# SWM190 register map
File version: 1.0
SWM190 Microcontroller registers
CPU: CM0 r1p0, little endian, 2 interrupt priority bits
Registers are 32-bit, read-write, no defined reset value unless marked. A register's access mark holds for its fields unless they carry their own. Offsets are from the block's base; lines under a group give offsets from that group; [hi:lo] are bit positions; {n}, {i} and the like mark numbered series; 'fields as' and 'values as' point back to an identical list; <NAME> marks a mode.

## Memory map
0x40000000 SYS size 0xAA088 — Registers group
0x40000800 DMA size 0x140 — Registers group
0x40003000 CORDIC size 0x20 — Registers group
0x40003800 DIV size 0x28 — Registers group
0x40005800 CACHE size 0x24 — Registers group
0x40040000 GPIOA size 0x80 — Registers group
0x40040800 GPIOB size 0x80
0x40041000 GPIOC size 0x80
0x40041800 GPIOD size 0x80
0x40042000 UART0 size 0x20 — Registers group
0x40042800 UART1 size 0x20
0x40043000 UART2 size 0x20
0x40043800 UART3 size 0x20
0x40044000 SPI0 size 0x24 — Registers group
0x40044800 SPI1 size 0x24
0x40046000 PWM0 size 0x3C — Registers group
0x40046040 PWM1 size 0x3C
0x40046080 PWM2 size 0x3C
0x400460C0 PWM3 size 0x3C
0x40046200 PWMG size 0x48 — Registers group
0x40046800 TIMR0 size 0x30 — Registers group
0x40046840 TIMR1 size 0x30
0x40046880 TIMR2 size 0x30
0x400468C0 TIMR3 size 0x30
0x40046C00 TIMRG size 0x44 — Registers group
0x40048800 BTIMR0 size 0x30
0x40048840 BTIMR1 size 0x30
0x40048880 BTIMR2 size 0x30
0x400488C0 BTIMR3 size 0x30
0x40048C00 BTIMRG size 0x44
0x40049000 ADC0 size 0xB4 — Registers group
0x40049800 ADC1 size 0xB4
0x4004A000 SFC size 0x28 — Registers group
0x4004B800 RTC size 0x34 — Registers group
0x400A0000 PORTA size 0x404 — Registers group
0x400A0010 PORTB size 0x404
0x400A0020 PORTC size 0x404
0x400A0030 PORTD size 0x404
0x400A0040 PORTE size 0x404
0x400A0800 WDT size 0x14 — Registers group
0x400A1000 GPIOE size 0x80
0x400A6000 I2C0 size 0x34 — Registers group
0x400A6800 I2C1 size 0x34

## SYS — Registers group
Base 0x40000000
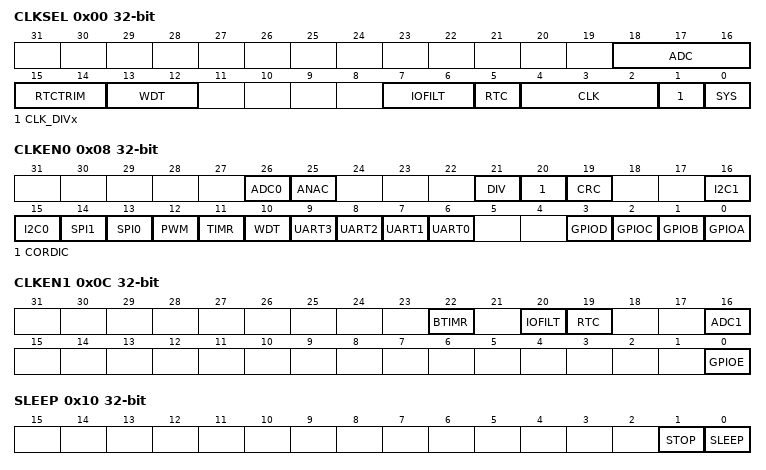
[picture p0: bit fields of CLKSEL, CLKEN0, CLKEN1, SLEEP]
0x00 CLKSEL
  [18:16] ADC, [15:14] RTCTRIM, [13:12] WDT, [7:6] IOFILT, [5] RTC, [4:2] CLK, [1] CLK_DIVx, [0] SYS
0x04 CLKDIVx_ON
0x08 CLKEN0
  [26] ADC0, [25] ANAC, [21] DIV, [20] CORDIC, [19] CRC, [16] I2C1, [15] I2C0, [14] SPI1, [13] SPI0, [12] PWM, [11] TIMR, [10] WDT, [n+6] UART{n} (n=0..3), [3] GPIOD, [2] GPIOC, [1] GPIOB, [0] GPIOA
0x0C CLKEN1
  [22] BTIMR, [20] IOFILT, [19] RTC, [16] ADC1, [0] GPIOE
0x10 SLEEP
  [1] STOP, [0] SLEEP
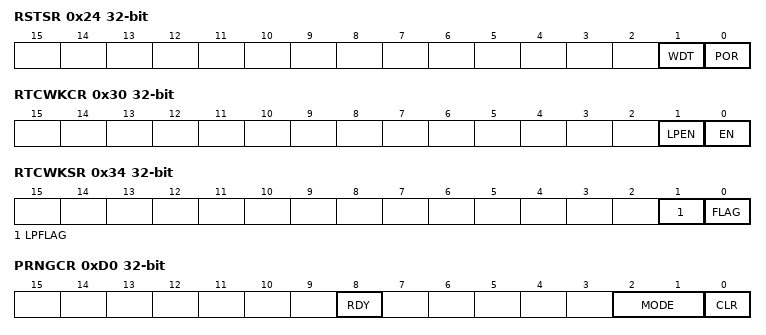
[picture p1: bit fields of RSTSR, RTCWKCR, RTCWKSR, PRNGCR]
0x24 RSTSR
  [1] WDT, [0] POR
0x30 RTCWKCR
  [1] LPEN, [0] EN
0x34 RTCWKSR
  [1] LPFLAG, [0] FLAG
{0x80+4i} CHIPID[{i}] (i=0..2) ro
0xD0 PRNGCR
  [8] RDY, [2:1] MODE, [0] CLR
0xD4 PRNGDL
0xD8 PRNGDH
0x100 PAWKEN
0x104 PBWKEN
0x108 PCWKEN
0x10C PDWKEN
0x110 PEWKEN
0x130 PAWKSR
0x134 PBWKSR
0x138 PCWKSR
0x13C PDWKSR
0x140 PEWKSR
0x400 IOFILT0
0x404 IOFILT1
0x720 PRSTEN
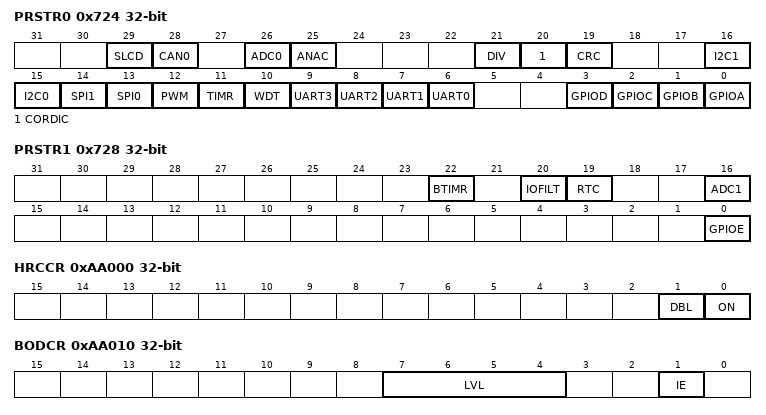
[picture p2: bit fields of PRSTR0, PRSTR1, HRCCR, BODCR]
0x724 PRSTR0
  [29] SLCD, [28] CAN0, [26] ADC0, [25] ANAC, [21] DIV, [20] CORDIC, [19] CRC, [16] I2C1, [15] I2C0, [14] SPI1, [13] SPI0, [12] PWM, [11] TIMR, [10] WDT, [n+6] UART{n} (n=0..3), [3] GPIOD, [2] GPIOC, [1] GPIOB, [0] GPIOA
0x728 PRSTR1
  [22] BTIMR, [20] IOFILT, [19] RTC, [16] ADC1, [0] GPIOE
0xAA000 HRCCR
  [1] DBL, [0] ON
0xAA010 BODCR
  [7:4] LVL, [1] IE
0xAA014 BODSR
  [0] IF
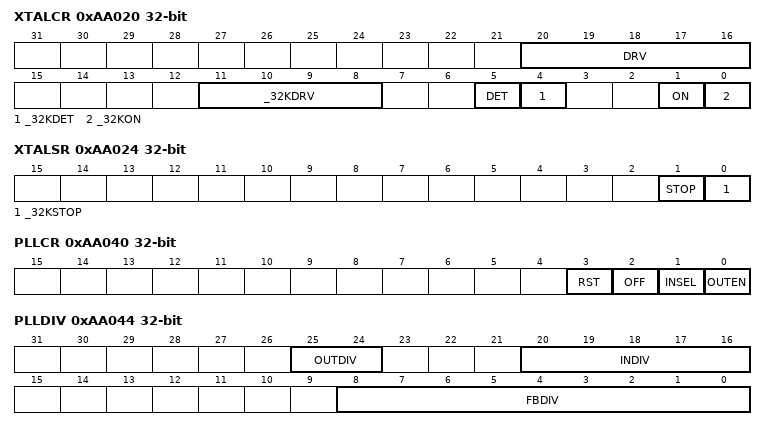
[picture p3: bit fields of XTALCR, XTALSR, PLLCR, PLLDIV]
0xAA020 XTALCR
  [20:16] DRV, [11:8] _32KDRV, [5] DET, [4] _32KDET, [1] ON, [0] _32KON
0xAA024 XTALSR
  [1] STOP, [0] _32KSTOP
0xAA040 PLLCR
  [3] RST, [2] OFF, [1] INSEL, [0] OUTEN
0xAA044 PLLDIV
  [25:24] OUTDIV, [20:16] INDIV, [8:0] FBDIV
0xAA04C PLLLOCK
0xAA050 LRCCR
  [0] ON
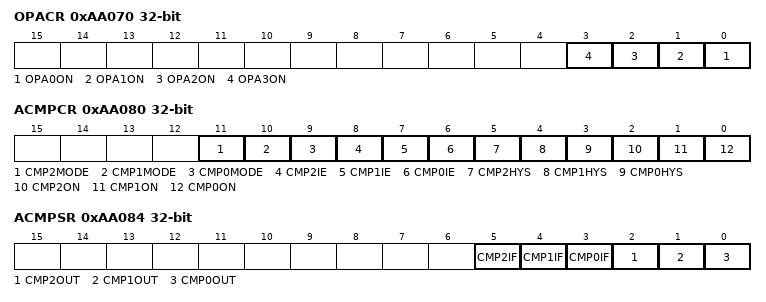
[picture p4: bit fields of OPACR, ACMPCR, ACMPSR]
0xAA070 OPACR
  [n] OPA{n}ON (n=0..3)
0xAA080 ACMPCR
  [11] CMP2MODE, [10] CMP1MODE, [9] CMP0MODE, [8] CMP2IE, [7] CMP1IE, [6] CMP0IE, [5] CMP2HYS, [4] CMP1HYS, [3] CMP0HYS, [2] CMP2ON, [1] CMP1ON, [0] CMP0ON
0xAA084 ACMPSR
  [5] CMP2IF, [4] CMP1IF, [3] CMP0IF, [2] CMP2OUT, [1] CMP1OUT, [0] CMP0OUT

## PORTA — Registers group
Base 0x400A0000
Same registers: PORTB 0x400A0010, PORTC 0x400A0020, PORTD 0x400A0030, PORTE 0x400A0040
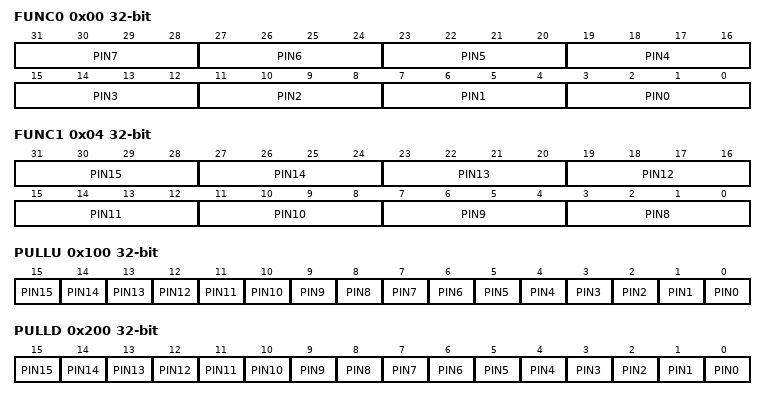
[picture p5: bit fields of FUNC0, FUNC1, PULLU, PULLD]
0x00 FUNC0
  [4n+3:4n] PIN{n} (n=0..7)
0x04 FUNC1
  [4n-29:4n-32] PIN{n} (n=8..15)
0x100 PULLU
  [n] PIN{n} (n=0..15)
0x200 PULLD
  [n] PIN{n} (n=0..15)
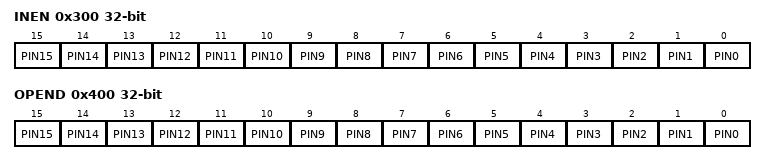
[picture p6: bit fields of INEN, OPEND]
0x300 INEN
  [n] PIN{n} (n=0..15)
0x400 OPEND
  [n] PIN{n} (n=0..15)
